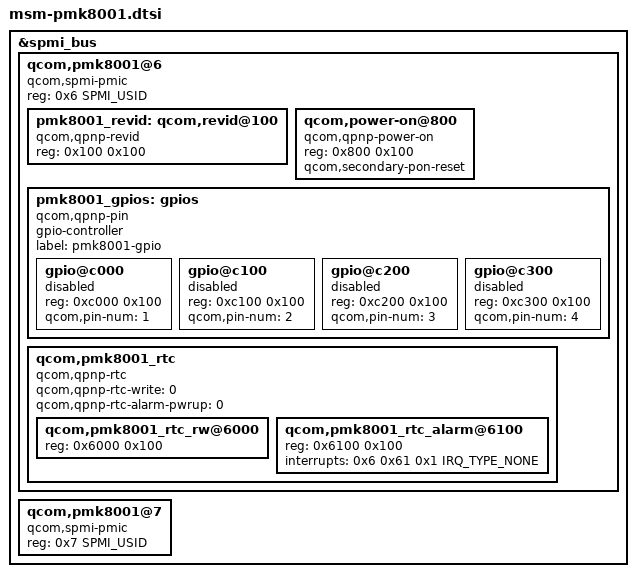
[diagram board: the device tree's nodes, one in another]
/* Copyright (c) 2015, The Linux Foundation. All rights reserved.
 *
 * This program is free software; you can redistribute it and/or modify
 * it under the terms of the GNU General Public License version 2 and
 * only version 2 as published by the Free Software Foundation.
 *
 * This program is distributed in the hope that it will be useful,
 * but WITHOUT ANY WARRANTY; without even the implied warranty of
 * MERCHANTABILITY or FITNESS FOR A PARTICULAR PURPOSE.  See the
 * GNU General Public License for more details.
 */

#include <dt-bindings/interrupt-controller/irq.h>
#include <dt-bindings/spmi/spmi.h>
&spmi_bus {
	qcom,pmk8001@6 {
		compatible ="qcom,spmi-pmic";
		reg = <0x6 SPMI_USID>;
		#address-cells = <2>;
		#size-cells = <0>;

		pmk8001_revid: qcom,revid@100 {
			compatible = "qcom,qpnp-revid";
			reg = <0x100 0x100>;
		};

		qcom,power-on@800 {
			compatible = "qcom,qpnp-power-on";
			reg = <0x800 0x100>;
			qcom,secondary-pon-reset;
		};

		pmk8001_gpios: gpios {
			compatible = "qcom,qpnp-pin";
			gpio-controller;
			#gpio-cells = <2>;
			#address-cells = <1>;
			#size-cells = <1>;
			label = "pmk8001-gpio";

			gpio@c000 {
				reg = <0xc000 0x100>;
				qcom,pin-num = <1>;
				status = "disabled";
			};

			gpio@c100 {
				reg = <0xc100 0x100>;
				qcom,pin-num = <2>;
				status = "disabled";
			};

			gpio@c200 {
				reg = <0xc200 0x100>;
				qcom,pin-num = <3>;
				status = "disabled";
			};

			gpio@c300 {
				reg = <0xc300 0x100>;
				qcom,pin-num = <4>;
				status = "disabled";
			};
		};

		qcom,pmk8001_rtc {
			compatible = "qcom,qpnp-rtc";
			#address-cells = <1>;
			#size-cells = <1>;
			qcom,qpnp-rtc-write = <0>;
			qcom,qpnp-rtc-alarm-pwrup = <0>;

			qcom,pmk8001_rtc_rw@6000 {
				reg = <0x6000 0x100>;
			};
			qcom,pmk8001_rtc_alarm@6100 {
				reg = <0x6100 0x100>;
				interrupts = <0x6 0x61 0x1 IRQ_TYPE_NONE>;
			};
		};
	};

	qcom,pmk8001@7 {
		compatible ="qcom,spmi-pmic";
		reg = <0x7 SPMI_USID>;
		#address-cells = <2>;
		#size-cells = <0>;
	};
};
